AUTOSAR XML (schema 4-3-0)
standard types defined: uint8
package /DataTypes/Base/Integers
  base type uint8_base: category=FIXED_LENGTH, base-type-size=8, base-type-encoding=unsigned, native-declaration=uint8_t
package /DataTypes/Application/Brake
  app type ThermalProtectionState: category=VALUE, compu {0=NORMAL (The brake is within its thermal limits.), 1=DERATED (The brake is hot and the permitted brake action is reduced.), 2=PROTECTIVE (The brake is overheated and only protective action is permitted.)}  # The thermal protection state of the brake.
package /DataTypes/MappingSets/Brake
  data type mapping set BrakeThermalMappings: data-type-map{application-data-type=ThermalProtectionState, implementation-data-type=uint8}  # Maps each application type of the vehicle to the implementation type that stores it.
package /PortInterfaces
  constant specification IPermittedBrakeAction_permittedAction_Init: value-spec=NORMAL
  sender receiver interface IPermittedBrakeAction
    data permittedAction: type=ThermalProtectionState, init-value=constant-reference=IPermittedBrakeAction_permittedAction_Init
package /ComponentTypes
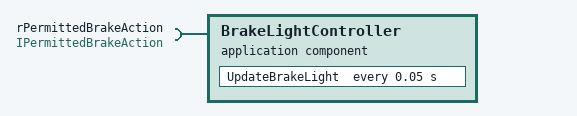
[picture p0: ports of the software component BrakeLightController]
  application sw component type BrakeLightController  # Switches the brake light warning on while the permitted brake action is reduced.
    require port rPermittedBrakeAction: nonqueued-receiver-com-spec{data-element=permittedAction, init-value=constant-reference=IPermittedBrakeAction_permittedAction_Init}, required-interface=IPermittedBrakeAction
    behavior BrakeLightController_InternalBehavior: data-type-mapping=BrakeThermalMappings, handle-termination-and-restart=NO-SUPPORT
      timing event TMT_UpdateBrakeLight: start-on-event=UpdateBrakeLight, period=0.05
      runnable UpdateBrakeLight
        data-receive-point-by-arguments:
          access R_rPermittedBrakeAction_permittedAction: accessed-variable=rPermittedBrakeAction.permittedAction
  swc implementation BrakeLightController_Implementation: behavior=BrakeLightController_InternalBehavior
